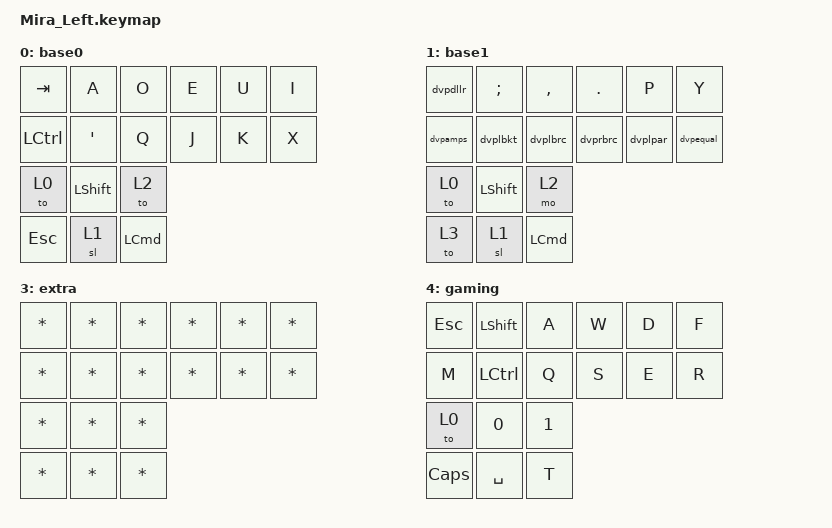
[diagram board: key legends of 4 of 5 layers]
#include <behaviors.dtsi>
#include <dt-bindings/zmk/keys.h>
#include <dt-bindings/zmk/bt.h>

#define COMBO_TIMEOUT 100
#define MACRO_TAP 10
#define MACRO_WAIT 0

#define P_S 7
#define P_T 2
#define P_P 3
#define P_H 4
#define P_K 8
#define P_W 9
#define P_R 10

/ {
        combos {
                compatible = "zmk,combos";
                combo_the {
                        layers = <2>;
                        timeout-ms = <50>;
                        key-positions = <P_S>;
                        bindings = <&kp I>;
                };
        };
};

/ {
        keymap {
		compatible = "zmk,keymap";

                base0 {
                        bindings = <
                                &kp TAB   &kp A      &kp O    &kp E &kp U &kp I
                                &kp LCTRL &kp SQT    &kp Q    &kp J &kp K &kp X
                                &to 0     &kp LSHIFT &to 2
                                &kp ESC   &sl 1      &kp LCMD
                        >;
                };

                base1 {
                        bindings = <
                                &dvpdllr &kp SEMI   &kp COMMA &kp DOT  &kp P    &kp Y 
                                &dvpamps &dvplbkt   &dvplbrc  &dvprbrc &dvplpar &dvpequal
                                &to 0    &kp LSHFT  &mo 2
                                &to 3    &sl 1      &kp LCMD
                        >;
                };

                steno {
                        bindings = <
                        >;
                };
        
                extra {
                        bindings = <
                                &kp STAR &kp STAR &kp STAR &kp STAR &kp STAR &kp STAR
                                &kp STAR &kp STAR &kp STAR &kp STAR &kp STAR &kp STAR
                                &kp STAR &kp STAR &kp STAR
                                &kp STAR &kp STAR &kp STAR
                        >;
                };
        
                gaming {
                        bindings = <
                                &kp ESC  &kp LSHFT &kp A  &kp W &kp D &kp F
                                &kp M    &kp LCTRL &kp Q  &kp S &kp E &kp R
                                &to 0    &kp N0    &kp N1
                                &kp CAPS &kp SPACE &kp T
                        >;
                };
        };
};

/ {
        behaviors {
                dvpdllr: dvp_dllr {
                        compatible = "zmk,behavior-mod-morph";
                        #binding-cells = <0>;
                        bindings = <&kp DLLR>, <&kp TILDE>;
                        mods = <(MOD_LSFT)>;
                };
                dvpamps: dvp_amps {
                        compatible = "zmk,behavior-mod-morph";
                        #binding-cells = <0>;
                        bindings = <&kp AMPS>, <&kp PRCNT>;
                        mods = <(MOD_LSFT)>;
                };
                dvplbkt: dvp_lbkt {
                        compatible = "zmk,behavior-mod-morph";
                        #binding-cells = <0>;
                        bindings = <&kp LBKT>, <&kp N7>;
                        mods = <(MOD_LSFT)>;
                };
                dvplbrc: dvp_lbrc {
                        compatible = "zmk,behavior-mod-morph";
                        #binding-cells = <0>;
                        bindings = <&kp LBRC>, <&kp N5>;
                        mods = <(MOD_LSFT)>;
                };
                dvprbrc: dvp_rbrc {
                        compatible = "zmk,behavior-mod-morph";
                        #binding-cells = <0>;
                        bindings = <&kp RBRC>, <&kp N3>;
                        mods = <(MOD_LSFT)>;
                };
                dvplpar: dvp_lpar {
                        compatible = "zmk,behavior-mod-morph";
                        #binding-cells = <0>;
                        bindings = <&kp LPAR>, <&kp N1>;
                        mods = <(MOD_LSFT)>;
                };
                dvpequal: dvp_equal {
                        compatible = "zmk,behavior-mod-morph";
                        #binding-cells = <0>;
                        bindings = <&kp EQUAL>, <&kp N9>;
                        mods = <(MOD_LSFT)>;
                };
        };
};
